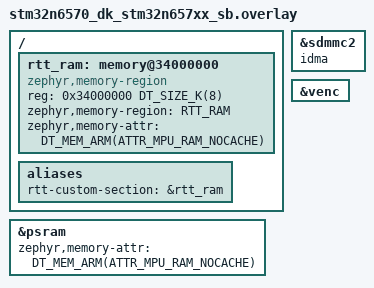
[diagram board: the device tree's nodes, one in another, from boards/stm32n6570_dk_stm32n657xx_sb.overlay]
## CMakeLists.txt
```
#******************************************************************************
#
# SPDX-FileCopyrightText: Copyright (c) 2026, UCSC Rocket Team
#
# SPDX-License-Identifier: BSD-3-Clause
#
#******************************************************************************

set(BOARD stm32n6570_dk/stm32n657xx/sb)
set(SHIELD st_b_cams_imx_mb1854)

cmake_minimum_required(VERSION 3.20.0)
find_package(Zephyr REQUIRED HINTS $ENV{ZEPHYR_BASE})
project(video_capture)

target_sources(app PRIVATE src/main.c src/jpeg_venc.c)

add_subdirectory(${CMAKE_CURRENT_LIST_DIR}/../../third_party/vc8000nanoe_jpeg vc8000nanoe_jpeg)
target_link_libraries(app PRIVATE vc8000nanoe_jpeg)
```

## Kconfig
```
#******************************************************************************
#
# SPDX-FileCopyrightText: Copyright (c) 2026, UCSC Rocket Team
#
# SPDX-License-Identifier: BSD-3-Clause
#
#******************************************************************************

mainmenu "MJPEG video capture sample application"

menu "Video capture configuration"

config VIDEO_CAPTURE_WIDTH
	int "Width of the video"
	default 1440
	help
	  Width the camera pipeline is asked to produce. Must be a multiple of 16.

config VIDEO_CAPTURE_HEIGHT
	int "Height of the video"
	default 1088
	help
	  Height the camera pipeline is asked to produce. Must be a multiple of 16.
	  The sensor image is cropped to this aspect ratio before it is scaled.

config VIDEO_CAPTURE_FPS
	int "Frames per second"
	default 30
	help
	  Frame rate asked of the sensor, which runs at 25 or 30 frames per second
	  at full resolution.

config VIDEO_CAPTURE_DURATION_S
	int "Length of the recording, in seconds"
	default 30
	range 1 3600

config VIDEO_CAPTURE_NUM_BUFS
	int "Number of capture buffers"
	default 4
	range 2 8
	help
	  Number of raw frames handed to the camera. The extra buffers let the
	  encoder fall briefly behind without the camera missing a frame.

config VIDEO_CAPTURE_NUM_JPEG_BUFS
	int "Number of JPEG buffers"
	default 64
	range 2 128
	help
	  Number of encoded frames that can wait for the SD card, which is what
	  absorbs the card's write stalls. Each takes a slot in
	  CONFIG_VIDEO_BUFFER_POOL_NUM_MAX.

config VIDEO_CAPTURE_JPEG_BUF_SIZE
	int "Size of each JPEG buffer, in bytes"
	default 262144
	help
	  The largest encoded frame that can be kept. A larger frame is dropped.
	  Must be a multiple of 512.

config VIDEO_CAPTURE_JPEG_QUALITY
	int "JPEG quality"
	default 50
	range 5 100
	help
	  Output JPEG quality for the encoder. Data rate rises steeply with quality,
	  and must stay under what the SD card can sustain.

config VIDEO_CAPTURE_CAMERA_POWER_UP_MS
	int "Wait for the camera module to power up, in ms"
	default 100
	range 0 1000
	help
	  The shield switches the camera module's power on at boot, and the sensor
	  driver starts talking to it over I2C soon after without waiting for the
	  module to come up. Boot waits this long in between.

config VIDEO_CAPTURE_WARMUP_FRAMES
	int "Frames to throw away before recording"
	default 8
	range 0 255
	help
	  The first frames after the sensor starts are unusable and must be discarded.

config VIDEO_CAPTURE_EXPOSURE
	int "Sensor exposure, in lines"
	default -1
	help
	  Value for VIDEO_CID_EXPOSURE. Set as -1 to keep the sensor driver default,
	  which is typically the maximum value.

config VIDEO_CAPTURE_GAIN
	int "Sensor analogue gain, in mdB"
	default -1
	help
	  Value for VIDEO_CID_ANALOGUE_GAIN. Set as -1 to keep the sensor driver
	  default.

endmenu

source "Kconfig.zephyr"
```

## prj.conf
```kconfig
CONFIG_VIDEO=y

# Zephyr's VENC driver, for the functions that jpeg_venc.c's encoder library uses
# to reach the hardware. It is only available along with its H.264 encoder.
CONFIG_VIDEO_ENCODER_H264=y

# CONFIG_VIDEO_CAPTURE_NUM_BUFS capture buffers plus
# CONFIG_VIDEO_CAPTURE_NUM_JPEG_BUFS JPEG buffers.
CONFIG_VIDEO_BUFFER_POOL_NUM_MAX=68

# Turn the CPU caches on.
CONFIG_CACHE_MANAGEMENT=y

# The VENC needs 8 byte aligned addresses, and the camera's DMA works in bursts.
CONFIG_VIDEO_BUFFER_POOL_ALIGN=64

# The FAT file system on the microSD card, which must already be formatted.
CONFIG_DISK_ACCESS=y
CONFIG_FILE_SYSTEM=y
CONFIG_FAT_FILESYSTEM_ELM=y

# Zephyr's default is to erase and reformat a card that fails to mount.
CONFIG_FS_FATFS_MOUNT_MKFS=n

# FatFs's sector buffer goes through the SD card's DMA, so match its alignment.
CONFIG_FS_FATFS_WINDOW_ALIGNMENT=64

CONFIG_MAIN_STACK_SIZE=4096

CONFIG_LOG=y
CONFIG_LOG_MODE_IMMEDIATE=y
```

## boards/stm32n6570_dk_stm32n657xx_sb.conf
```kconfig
# Video buffer pool in the external PSRAM: 4 x 2350080 byte frames plus
# 64 x 262144 byte JPEG buffers, with some room for the heap's own overhead.
CONFIG_MEMC=y
CONFIG_VIDEO_BUFFER_POOL_ZEPHYR_REGION=y
CONFIG_VIDEO_BUFFER_POOL_ZEPHYR_REGION_NAME="PSRAM"
CONFIG_VIDEO_BUFFER_POOL_HEAP_SIZE=26400000

# The VENC driver's heap, which only holds the JPEG encoder's own state. The
# hardware does not read it, so it stays out of the uncached PSRAM.
CONFIG_VIDEO_STM32_VENC_HEAP_ZEPHYR_REGION=n
CONFIG_VIDEO_STM32_VENC_HEAP_SIZE=65536

# Use RTT instead of UART
CONFIG_USE_SEGGER_RTT=y
CONFIG_RTT_CONSOLE=y
CONFIG_SEGGER_RTT_BUFFER_SIZE_UP=4096
CONFIG_SEGGER_RTT_SECTION_CUSTOM_DTS_REGION=y
CONFIG_SERIAL=n
CONFIG_UART_CONSOLE=n
```

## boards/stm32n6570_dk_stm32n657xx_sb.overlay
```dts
/*
 * SPDX-FileCopyrightText: Copyright (c) 2026, UCSC Rocket Team
 *
 * SPDX-License-Identifier: BSD-3-Clause
 *
 */

#include <zephyr/dt-bindings/memory-attr/memory-attr-arm.h>

/ {
	/*
	 * Link the RTT control block and buffers into the first 8 kB of AXISRAM1,
	 * which is not used in any other respect. Marked uncached.
	 */
	rtt_ram: memory@34000000 {
		compatible = "zephyr,memory-region";
		reg = <0x34000000 DT_SIZE_K(8)>;
		zephyr,memory-region = "RTT_RAM";
		zephyr,memory-attr = <DT_MEM_ARM(ATTR_MPU_RAM_NOCACHE)>;
	};

	aliases {
		rtt-custom-section = &rtt_ram;
	};
};

/*
 * Move the SD card's data with SDMMC2's internal DMA rather than by interrupt.
 *
 * The driver leaves the card in its default speed mode, which is rated to
 * 25 MHz, but runs the bus directly from SDMMC2's 48 MHz clock. If a card gives
 * CRC errors, clk-div = <1> brings the bus down to 24 MHz.
 */
&sdmmc2 {
	idma;
};

/* The VENC, which encodes the JPEGs. */
&venc {
	status = "okay";
};

/*
 * Leave the PSRAM uncached. It holds the frames and the JPEGs, and the hardware
 * does nearly all of the reading and writing there. The CPU only writes each
 * JPEG's header and padding, the VENC writing right beside the header.
 */
&psram {
	zephyr,memory-attr = <DT_MEM_ARM(ATTR_MPU_RAM_NOCACHE)>;
};
```

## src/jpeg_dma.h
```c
//*****************************************************************************
//
// SPDX-FileCopyrightText: Copyright (c) 2026, UCSC Rocket Team
//
// SPDX-License-Identifier: BSD-3-Clause
//
//*****************************************************************************

//*****************************************************************************
//
//! @file jpeg_dma.h
//!
//! @brief Encode NV12 frames with the STM32N6 JPEG codec over HPDMA.
//!
//! @addtogroup video_capture
//! @{
//
//*****************************************************************************

#ifndef JPEG_DMA_H
#define JPEG_DMA_H

#include <stddef.h>
#include <stdint.h>

//
// The size of an output buffer must be a multiple of this.
//
#define JPEG_DMA_OUT_MULTIPLE   4096U

//*****************************************************************************
//
//! @brief Bring up the JPEG codec and its two DMA channels.
//!
//! The picture size comes from CONFIG_VIDEO_CAPTURE_WIDTH and
//! CONFIG_VIDEO_CAPTURE_HEIGHT.
//!
//! @param quality JPEG quality, from 1 to 100.
//!
//! @return 0 on success, or a negative errno otherwise.
//
//*****************************************************************************
int jpeg_dma_init(uint32_t quality);

//*****************************************************************************
//
//! @brief Encode one NV12 frame, and wait for it to finish.
//!
//! The caller must already have invalidated the frame from the data cache.
//! On return, the part of out that was written may be dirty in the data cache,
//! and the caller is responsible for flushing it.
//!
//! @param frame The NV12 frame, with a luma pitch of the frame width.
//! @param out Where to write the JPEG. Must be 4 byte aligned.
//! @param out_size Size of out, in bytes. Any part beyond the last multiple of
//!        JPEG_DMA_OUT_MULTIPLE goes unused.
//! @param[out] out_len Size of the JPEG, in bytes. This is a multiple of 4, so
//!             up to 3 bytes of padding can follow the end of the image.
//!
//! @return 0 on success, -ENOSPC if the JPEG did not fit, or another negative
//!         errno otherwise. After a failure, the encoder has been reset and is
//!         ready for another frame.
//
//*****************************************************************************
int jpeg_dma_encode(const uint8_t *frame, uint8_t *out, size_t out_size, size_t *out_len);

#endif // JPEG_DMA_H

//*****************************************************************************
//
// End Doxygen group.
//! @}
//
//*****************************************************************************
```

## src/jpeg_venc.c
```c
//*****************************************************************************
//
// SPDX-FileCopyrightText: Copyright (c) 2026, UCSC Rocket Team
//
// SPDX-License-Identifier: BSD-3-Clause
//
//*****************************************************************************

//*****************************************************************************
//
//! @file jpeg_venc.c
//!
//! @brief Encode NV12 frames as JPEGs with the STM32N6 VENC peripheral.
//!
//! @addtogroup video_capture
//! @{
//!
//! The VENC reads the frame straight from memory and writes the JPEG straight
//! to memory, so an encode costs the CPU almost nothing. The separate JPEG codec
//! cannot do this: it needs its input rearranged into MCU blocks first, which
//! would take about 45% of the CPU at this resolution and frame rate.
//!
//! The encoder is ST's library in third_party/vc8000nanoe_jpeg, which reaches
//! the hardware through the EWL functions in Zephyr's VENC driver. Zephyr itself
//! only supports H.264 on the VENC, which leaves three things to do here:
//!
//! 1. Turn on the APB5 bus. The driver only turns on the VENC's own clock, so
//!    without this its registers read as 0 and the library decides that the
//!    hardware has no JPEG encoder.
//!
//! 2. Keep the scheduler running during an encode. The driver's interrupt is a
//!    direct ISR that does not reschedule, so a waiting thread only wakes at the
//!    next ordinary interrupt, which could be a whole frame later. A short
//!    periodic timer provides those interrupts.
//!
//! 3. Avoid CONFIG_ASSERT, as the driver's EWLInit() asserts that its client is
//!    the H.264 encoder.
//
//*****************************************************************************

//
// Standard C library
//
#include <errno.h>                  // Error codes

//
// Zephyr kernel and drivers
//
#include <zephyr/kernel.h>          // Timers
#include <zephyr/device.h>          // Device readiness
#include <zephyr/logging/log.h>     // Logging over the RTT console
#include <zephyr/sys/util.h>        // CLAMP()

//
// STM32Cube HAL
//
#include <soc.h>                    // RCC registers and the RIF

//
// ST's encoder library
//
#include <jpegencapi.h>             // JPEG encoder API

#include "jpeg_venc.h"

//*****************************************************************************
//
// Constants.
//
//*****************************************************************************

#define VENC_NODE               DT_NODELABEL(venc)

#define FRAME_WIDTH             CONFIG_VIDEO_CAPTURE_WIDTH
#define FRAME_HEIGHT            CONFIG_VIDEO_CAPTURE_HEIGHT

#define QUANT_TABLE_SIZE        64U

//
// The VENC's security attributes in the RIF, as set at boot.
//
#define VENC_RIF_ATTRIBUTES     (RIF_ATTRIBUTE_SEC | RIF_ATTRIBUTE_PRIV)

BUILD_ASSERT(FRAME_WIDTH % 16 == 0 && FRAME_HEIGHT % 16 == 0,
             "The JPEG encoder works in 16x16 blocks");

BUILD_ASSERT(!IS_ENABLED(CONFIG_ASSERT),
             "Zephyr's VENC driver asserts that it is only used for H.264");

//
// The example quantization tables in ISO/IEC 10918-1, annexes K.1 and K.2. The
// encoder takes them in this raster order, although jpegencapi.h says zigzag.
//
static const uint8_t base_quant_luma[QUANT_TABLE_SIZE] = {
    16, 11, 10, 16,  24,  40,  51,  61,
    12, 12, 14, 19,  26,  58,  60,  55,
    14, 13, 16, 24,  40,  57,  69,  56,
    14, 17, 22, 29,  51,  87,  80,  62,
    18, 22, 37, 56,  68, 109, 103,  77,
    24, 35, 55, 64,  81, 104, 113,  92,
    49, 64, 78, 87, 103, 121, 120, 101,
    72, 92, 95, 98, 112, 100, 103,  99,
};

static const uint8_t base_quant_chroma[QUANT_TABLE_SIZE] = {
    17, 18, 24, 47, 99, 99, 99, 99,
    18, 21, 26, 66, 99, 99, 99, 99,
    24, 26, 56, 99, 99, 99, 99, 99,
    47, 66, 99, 99, 99, 99, 99, 99,
    99, 99, 99, 99, 99, 99, 99, 99,
    99, 99, 99, 99, 99, 99, 99, 99,
    99, 99, 99, 99, 99, 99, 99, 99,
    99, 99, 99, 99, 99, 99, 99, 99,
};

//*****************************************************************************
//
// Globals.
//
//*****************************************************************************

LOG_MODULE_REGISTER(jpeg_venc);

static JpegEncInst encoder;
static uint8_t quant_luma[QUANT_TABLE_SIZE];
static uint8_t quant_chroma[QUANT_TABLE_SIZE];

//
// Does nothing itself. Its interrupt gives the scheduler a chance to run.
//
K_TIMER_DEFINE(scheduler_nudge, NULL, NULL);

//*****************************************************************************
//
// Scale a base quantization table to a JPEG quality.
//
//*****************************************************************************
static void
scale_quant_table(const uint8_t *base, uint8_t *table, uint32_t quality)
{
    uint32_t scale = (quality < 50U) ? (5000U / quality) : (200U - (2U * quality));

    for ( uint32_t i = 0; i < QUANT_TABLE_SIZE; i++ )
    {
        uint32_t value = ((base[i] * scale) + 50U) / 100U;

        table[i] = (uint8_t)CLAMP(value, 1U, 255U);
    }
}

//*****************************************************************************
//
// Create the encoder instance.
//
//*****************************************************************************
static int
encoder_start(void)
{
    const JpegEncCfg config = {
        .inputWidth = FRAME_WIDTH,
        .inputHeight = FRAME_HEIGHT,
        .codingWidth = FRAME_WIDTH,
        .codingHeight = FRAME_HEIGHT,
        .qTableLuma = quant_luma,
        .qTableChroma = quant_chroma,
        .frameType = JPEGENC_YUV420_SEMIPLANAR,
        .rotation = JPEGENC_ROTATE_0,
        .codingType = JPEGENC_WHOLE_FRAME,
        .codingMode = JPEGENC_420_MODE,
        .unitsType = JPEGENC_NO_UNITS,
        .markerType = JPEGENC_SINGLE_MARKER,
        .xDensity = 1,
        .yDensity = 1,
    };
    JpegEncRet ret;

    ret = JpegEncInit(&config, &encoder);
    if ( ret != JPEGENC_OK )
    {
        LOG_ERR("JpegEncInit() returned %d", ret);
        return -EIO;
    }

    ret = JpegEncSetPictureSize(encoder, &config);
    if ( ret != JPEGENC_OK )
    {
        LOG_ERR("JpegEncSetPictureSize() returned %d", ret);
        JpegEncRelease(encoder);
        encoder = NULL;
        return -EIO;
    }

    return 0;
}

//*****************************************************************************
//
// Bring up the JPEG encoder.
//
//*****************************************************************************
int
jpeg_venc_init(uint32_t quality)
{
    if ( !device_is_ready(DEVICE_DT_GET(VENC_NODE)) )
    {
        LOG_ERR("The VENC is not ready");
        return -ENODEV;
    }

    WRITE_REG(RCC->BUSENSR, RCC_BUSENSR_APB5ENS);

    scale_quant_table(base_quant_luma, quant_luma, quality);
    scale_quant_table(base_quant_chroma, quant_chroma, quality);

    return encoder_start();
}

//*****************************************************************************
//
// Check the VENC's security attributes in the RIF, and restore them if they were
// lost, returning whether they were intact.
//
// While a debugger connects, these can be cleared. The VENC then carries on as if
// nothing were wrong, but cannot reach the PSRAM, so it reads a blank frame and writes
// nothing, leaving whatever was already in the output buffer. It reports success, and
// neither resetting it nor starting the encoder again helps.
//
//*****************************************************************************
static bool
venc_access_intact(void)
{
    if ( HAL_RIF_RISC_GetSlaveSecureAttributes(RIF_RISC_PERIPH_INDEX_VENC) == VENC_RIF_ATTRIBUTES )
    {
        return true;
    }

    LOG_WRN("The VENC lost its access to memory, and it has been restored");
    HAL_RIF_RISC_SetSlaveSecureAttributes(RIF_RISC_PERIPH_INDEX_VENC, VENC_RIF_ATTRIBUTES);

    return false;
}

//*****************************************************************************
//
// Encode one NV12 frame, and wait for it to finish.
//
//*****************************************************************************
int
jpeg_venc_encode(const uint8_t *frame, uint8_t *out, size_t out_size, size_t *out_len)
{
    const uint8_t *chroma = frame + (FRAME_WIDTH * FRAME_HEIGHT);
    const JpegEncIn input = {
        .frameHeader = 1,
        .busLum = (size_t)frame,
        .busCb = (size_t)chroma,
        .busCr = (size_t)chroma,
        .pLum = frame,
        .pCb = chroma,
        .pCr = chroma,
        .pOutBuf = out,
        .busOutBuf = (size_t)out,
        .outBufSize = (u32)out_size,
    };
    JpegEncOut output = {0};
    JpegEncRet ret;

    (void)venc_access_intact();

    k_timer_start(&scheduler_nudge, K_MSEC(1), K_MSEC(1));
    ret = JpegEncEncode(encoder, &input, &output, NULL, NULL);
    k_timer_stop(&scheduler_nudge);

    //
    // Nothing is wrong with the encoder if this frame was lost, so there is no need
    // to start it again.
    //
    if ( !venc_access_intact() )
    {
        return -EIO;
    }

    if ( ret == JPEGENC_FRAME_READY )
    {
        *out_len = output.jfifSize;
        return 0;
    }

    if ( ret == JPEGENC_OUTPUT_BUFFER_OVERFLOW )
    {
        return -ENOSPC;
    }

    //
    // Start again with a new instance, to leave nothing of this failure behind.
    // If that fails, there is no instance, and the library rejects the next frame
    // for that reason, which brings this back here to try again.
    //
    LOG_ERR("JpegEncEncode() returned %d", ret);
    JpegEncRelease(encoder);
    encoder = NULL;
    if ( encoder_start() < 0 )
    {
        LOG_ERR("Could not restart the encoder");
    }

    return -EIO;
}

//*****************************************************************************
//
// End Doxygen group.
//! @}
//
//*****************************************************************************
```

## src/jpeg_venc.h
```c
//*****************************************************************************
//
// SPDX-FileCopyrightText: Copyright (c) 2026, UCSC Rocket Team
//
// SPDX-License-Identifier: BSD-3-Clause
//
//*****************************************************************************

//*****************************************************************************
//
//! @file jpeg_venc.h
//!
//! @brief Encode NV12 frames as JPEGs with the STM32N6 VENC peripheral.
//!
//! @addtogroup video_capture
//! @{
//
//*****************************************************************************

#ifndef JPEG_VENC_H
#define JPEG_VENC_H

#include <stddef.h>
#include <stdint.h>

//*****************************************************************************
//
//! @brief Bring up the JPEG encoder.
//!
//! The picture size comes from CONFIG_VIDEO_CAPTURE_WIDTH and
//! CONFIG_VIDEO_CAPTURE_HEIGHT.
//!
//! @param quality JPEG quality, from 1 to 100.
//!
//! @return 0 on success, or a negative errno otherwise.
//
//*****************************************************************************
int jpeg_venc_init(uint32_t quality);

//*****************************************************************************
//
//! @brief Encode one NV12 frame, and wait for it to finish.
//!
//! The VENC reads the frame and writes the JPEG directly, so neither can be in
//! cached memory.
//!
//! @param frame The NV12 frame, with a luma pitch of the frame width.
//! @param out Where to write the JPEG. Must be 8 byte aligned.
//! @param out_size Size of out, in bytes. The VENC stops a little short of the
//!        end, so a JPEG cannot quite fill it.
//! @param[out] out_len Size of the JPEG, in bytes.
//!
//! @return 0 on success, -ENOSPC if the JPEG did not fit, or another negative
//!         errno otherwise. The encoder can take another frame in all cases.
//
//*****************************************************************************
int jpeg_venc_encode(const uint8_t *frame, uint8_t *out, size_t out_size, size_t *out_len);

#endif // JPEG_VENC_H

//*****************************************************************************
//
// End Doxygen group.
//! @}
//
//*****************************************************************************
```
